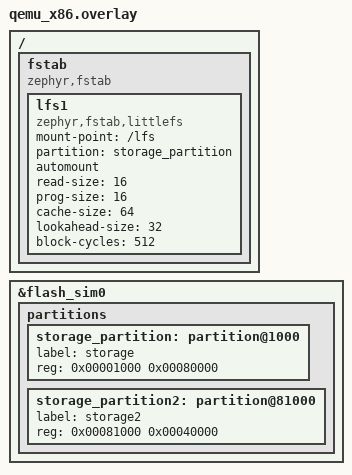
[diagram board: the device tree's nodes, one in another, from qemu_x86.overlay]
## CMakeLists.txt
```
cmake_minimum_required(VERSION 3.20.0)

set(ZEPHYR_EXTRA_MODULES ${CMAKE_CURRENT_SOURCE_DIR}/modules/lua)
set(DTC_OVERLAY_FILE "qemu_x86.overlay")

find_package(Zephyr)
project(zephyr_qemu_lua_demo)

set(embedded_lua_scripts "")
file(GLOB files "${CMAKE_CURRENT_SOURCE_DIR}/src/lua_scripts/*.lua")
foreach(file ${files})
    get_filename_component(filename ${file} NAME)
    get_filename_component(filepath ${file} PATH)
    message(STATUS "embedding ${filepath}/${filename} into elf")
    add_custom_command(
        OUTPUT ${CMAKE_CURRENT_BINARY_DIR}/embluaobj/${filename}.o
        WORKING_DIRECTORY ${filepath}
        COMMAND ${CMAKE_OBJCOPY}
        ARGS -I binary --output-target elf32-i386 --binary-architecture i386 ${filename} ${CMAKE_CURRENT_BINARY_DIR}/embluaobj/${filename}.o
    )
    # Find a way to automatically choose output-target and binary-architecture
    #   e.g. using : $<TARGET_PROPERTY:bintools,elfconvert_flag_outtarget>
    list(APPEND embedded_lua_scripts ${CMAKE_CURRENT_BINARY_DIR}/embluaobj/${filename}.o)
endforeach()

FILE(GLOB app_sources src/*.c*)
target_sources(app PRIVATE ${app_sources} ${embedded_lua_scripts})

zephyr_linker_sources(SECTIONS iterables.ld)
```

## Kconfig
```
mainmenu "Networking ZEPHYR QEMU AWS MQTT sample application"

config CLOUD_AWS_HOSTNAME
	string "AWS MQTT hostname"
	help
		Hostname of the AWS MQTT broker.

config CLOUD_AWS_PORT
	int "AWS MQTT port"
	default 8883
	help
		Port of the AWS MQTT broker.

config CLOUD_AWS_DEVICE_NAME
	string "AWS Device name"
	help
		Name of the device.

config CLOUD_AWS_QOS
	int "AWS MQTT QoS"
	default 0
	help
		Quality of Service of the AWS MQTT broker.

config CLOUD_AWS_PAYLOAD_BUFFER_SIZE
	int "AWS MQTT payload buffer size"
	default 4096
	help
		Size of the payload buffer.

source "Kconfig.zephyr"
```

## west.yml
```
# Copyright (c) 2021 Nordic Semiconductor ASA
# SPDX-License-Identifier: Apache-2.0

manifest:
  self:
    path: zephyr-qemu-dev

  remotes:
    - name: zephyrproject-rtos
      url-base: https://github.com/zephyrproject-rtos

  projects:
    - name: zephyr
      remote: zephyrproject-rtos
      revision: main
      import: true
```

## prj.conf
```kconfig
CONFIG_PRINTK=y

###############################################################################

CONFIG_QEMU_ICOUNT=n

###############################################################################

# CONFIG_NEWLIB_LIBC=y
# CONFIG_NEWLIB_LIBC_MIN_REQUIRED_HEAP_SIZE=2048

CONFIG_MINIMAL_LIBC=y
CONFIG_MINIMAL_LIBC_MALLOC=y
CONFIG_MINIMAL_LIBC_MALLOC_ARENA_SIZE=2048

CONFIG_SYS_MEM_BLOCKS=y
```

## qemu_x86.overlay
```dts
/delete-node/ &storage_partition;

/ {
	fstab {
		compatible = "zephyr,fstab";
		lfs1: lfs1 {
			compatible = "zephyr,fstab,littlefs";
			mount-point = "/lfs";
			partition = <&storage_partition>;
			automount;
			read-size = <16>;
			prog-size = <16>;
			cache-size = <64>;
			lookahead-size = <32>;
			block-cycles = <512>;
		};
	};
};

&flash_sim0 {
	partitions {
		storage_partition: partition@1000 {
			label = "storage";
			reg = <0x00001000 0x00080000>;
		};

		/* Todo, use this partition with FATFS NAND: (DISK_DRIVER_FLASH) 
		 * With big sector size
		 * erase-block-size = < 0x400 >;
		 * write-block-size = < 0x4 >;
		 */
		storage_partition2: partition@81000 {
			label = "storage2";
			reg = <0x00081000 0x00040000>;
		};
    };
};
```

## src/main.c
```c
#include <zephyr.h>

#include <stdio.h>
#include <stdlib.h>
#include <errno.h>
#include <stdio.h>

#include <sys/mem_blocks.h>

SYS_MEM_BLOCKS_DEFINE_STATIC(memblocks, 0x100, 4, 4);

int main(void)
{
	void *blocks[4];
	int ret = sys_mem_blocks_alloc(&memblocks, 2, blocks);
	printk("sys_mem_blocks_alloc : ret: %d\n", ret);

	if (ret == 0) {
		printk("blocks: %p %p\n", blocks[0], blocks[1]);
		sys_mem_blocks_free(&memblocks, 2, blocks);
		printk("sys_mem_blocks_free : ret: %d\n", ret);
	}

	void *alloc;
	ret = sys_mem_blocks_alloc(&memblocks, 1, &alloc);
	printk("sys_mem_blocks_alloc : ret: %d\n", ret);

	if (ret == 0) {
		printk("blocks: %p\n", alloc);
		sys_mem_blocks_free(&memblocks, 1, &alloc);
		printk("sys_mem_blocks_free : ret: %d\n", ret);
	}

	return 0;
}
```

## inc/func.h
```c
#ifndef _FUNC_H_
#define _FUNC_H_

void hello(void);

#endif /* _FUNC_H_ */
```

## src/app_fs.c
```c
/*
 * Copyright (c) 2022 Lucas Dietrich
 * Copyright (c) 2022 Lukasz Majewski, DENX Software Engineering GmbH
 * Copyright (c) 2019 Peter Bigot Consulting, LLC
 *
 * SPDX-License-Identifier: Apache-2.0
 */

/* Sample which uses the filesystem API with littlefs */

#include <stdio.h>

#include <zephyr.h>
#include <device.h>

#include <fs/fs.h>
#include <fs/littlefs.h>
#include <ff.h>

#include <storage/flash_map.h>
#include <storage/disk_access.h>

#include <logging/log.h>
LOG_MODULE_REGISTER(app_fs, LOG_LEVEL_DBG);

static int lsdir(const char *path)
{
	int res;
	struct fs_dir_t dirp;
	static struct fs_dirent entry;

	fs_dir_t_init(&dirp);

	/* Verify fs_opendir() */
	res = fs_opendir(&dirp, path);
	if (res) {
		LOG_ERR("Error opening dir %s [%d]", path, res);
		return res;
	}

	LOG_INF("Listing dir %s ...", path);
	for (;;) {
		/* Verify fs_readdir() */
		res = fs_readdir(&dirp, &entry);

		/* entry.name[0] == 0 means end-of-dir */
		if (res || entry.name[0] == 0) {
			if (res < 0) {
				LOG_ERR("Error reading dir [%d]", res);
			}
			break;
		}

		if (entry.type == FS_DIR_ENTRY_DIR) {
			LOG_INF("[DIR ] %s", entry.name);
		} else {
			LOG_INF("[FILE] %s (size = %zu)",
				   entry.name, entry.size);
		}
	}

	/* Verify fs_closedir() */
	fs_closedir(&dirp);

	return res;
}


static int littlefs_flash_erase(unsigned int id)
{
	const struct flash_area *pfa;
	int rc;

	rc = flash_area_open(id, &pfa);
	if (rc < 0) {
		LOG_ERR("FAIL: unable to find flash area %u: %d",
			id, rc);
		return rc;
	}

	LOG_INF("Area %u at 0x%x on %s for %u bytes",
		   id, (unsigned int)pfa->fa_off, pfa->fa_dev_name,
		   (unsigned int)pfa->fa_size);

	/* Optional wipe flash contents */
	if (IS_ENABLED(CONFIG_APP_WIPE_STORAGE)) {
		rc = flash_area_erase(pfa, 0, pfa->fa_size);
		LOG_ERR("Erasing flash area ... %d", rc);
	}

	flash_area_close(pfa);
	return rc;
}

/* LittleFS mount point */
#define LFS_PARTITION_NODE DT_NODELABEL(lfs1)
#define FATFS_PARTITION_NODE DT_NODELABEL(fatfs1)

#if DT_NODE_EXISTS(LFS_PARTITION_NODE)
FS_FSTAB_DECLARE_ENTRY(LFS_PARTITION_NODE);
#else /* LFS_PARTITION_NODE */
FS_LITTLEFS_DECLARE_DEFAULT_CONFIG(storage);
static struct fs_mount_t lfs_storage_mnt = {
	.type = FS_LITTLEFS,
	.fs_data = &storage,
	.storage_dev = (void *)FLASH_AREA_ID(storage),
	.mnt_point = "/lfs",
};
#endif /* LFS_PARTITION_NODE */

	struct fs_mount_t *mp =
#if DT_NODE_EXISTS(LFS_PARTITION_NODE)
		&FS_FSTAB_ENTRY(LFS_PARTITION_NODE)
#else
		&lfs_storage_mnt
#endif
		;

/* FATFS mount point */
static FATFS fat_fs;

static struct fs_mount_t mp2 = {
	.type = FS_FATFS,
	.fs_data = &fat_fs,
};

static const char *disk_mount_pt = "/RAM:";

int fs_stats(void)
{
	int rc;
	struct fs_statvfs sbuf;

	rc = fs_statvfs(mp->mnt_point, &sbuf);
	if (rc < 0) {
		LOG_INF("FAIL: statvfs: %d", rc);
		goto exit;
	}

	LOG_INF("%s: bsize = %lu ; frsize = %lu ;"
		   " blocks = %lu ; bfree = %lu",
		   mp->mnt_point,
		   sbuf.f_bsize, sbuf.f_frsize,
		   sbuf.f_blocks, sbuf.f_bfree);

	rc = lsdir(mp->mnt_point);
	if (rc < 0) {
		LOG_INF("FAIL: lsdir %s: %d", mp->mnt_point, rc);
		goto exit;
	}

	rc = 0;

exit:
	return rc;
}

static int fatfs_mount(void)
{
	int rc;

	/* raw disk i/o */
	do {
		static const char *disk_pdrv = "RAM";
		uint64_t memory_size_mb;
		uint32_t block_count;
		uint32_t block_size;

		if (disk_access_init(disk_pdrv) != 0) {
			LOG_ERR("Storage init ERROR!");
			break;
		}

		if (disk_access_ioctl(disk_pdrv,
				DISK_IOCTL_GET_SECTOR_COUNT, &block_count)) {
			LOG_ERR("Unable to get sector count");
			break;
		}
		LOG_INF("Block count %u", block_count);

		if (disk_access_ioctl(disk_pdrv,
				DISK_IOCTL_GET_SECTOR_SIZE, &block_size)) {
			LOG_ERR("Unable to get sector size");
			break;
		}
		printk("Sector size %u\n", block_size);

		memory_size_mb = (uint64_t)block_count * block_size;
		printk("Memory Size(MB) %u\n", (uint32_t)(memory_size_mb >> 20));
	} while (0);

	mp2.mnt_point = disk_mount_pt;

	rc = fs_mount(&mp2);

	if (rc == FR_OK) {
		printk("Disk mounted.\n");
		lsdir(disk_mount_pt);
	} else {
		printk("Error mounting disk.\n");
	}

	return rc;
}

static int littlefs_mount(void)
{
	int rc;

	rc = littlefs_flash_erase((uintptr_t)mp->storage_dev);
	if (rc < 0) {
		return rc;
	}

	/* Do not mount if auto-mount has been enabled */
#if !DT_NODE_EXISTS(LFS_PARTITION_NODE) ||						\
	!(FSTAB_ENTRY_DT_MOUNT_FLAGS(LFS_PARTITION_NODE) & FS_MOUNT_FLAG_AUTOMOUNT)
	rc = fs_mount(mp);
	if (rc < 0) {
		LOG_INF("FAIL: mount id %" PRIuPTR " at %s: %d",
		       (uintptr_t)mp->storage_dev, mp->mnt_point, rc);
		return rc;
	}
	LOG_INF("%s mount: %d", mp->mnt_point, rc);
#else
	LOG_INF("%s automounted", mp->mnt_point);
#endif

	return rc;
}

int fs_init(void)
{
	int rc;

	rc = fatfs_mount();
	if (rc < 0) {
		return rc;
	}

	rc = littlefs_mount();

	return rc;
}

int fs_file_add(const char *fname, const char *data, size_t size)
{
	int rc, written = 0;
	struct fs_file_t file;

	fs_file_t_init(&file);
	rc = fs_open(&file, fname, FS_O_CREATE | FS_O_WRITE);
	if (rc < 0) {
		LOG_ERR("FAIL: open %s: %d", log_strdup(fname), rc);
		return rc;
	}

	rc = fs_seek(&file, 0, FS_SEEK_SET);
	if (rc < 0) {
		LOG_ERR("FAIL: seek %s: %d", log_strdup(fname), rc);
		goto out;
	}

	rc = fs_write(&file, data, size);
	if (rc < 0) {
		LOG_ERR("FAIL: write %s: %d", log_strdup(fname), rc);
		goto out;
	}

	written = rc;

out:
	rc = fs_close(&file);
	if (rc < 0) {
		LOG_ERR("FAIL: close %s: %d", log_strdup(fname), rc);
		return rc;
	}

	return written;
}
```

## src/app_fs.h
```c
#ifndef _LUA_FS_H_
#define _LUA_FS_H_

#include <fs/fs.h>

extern struct fs_mount_t *mp;

int fs_init(void);

int fs_file_add(const char *name, const char *data, size_t size);

int fs_stats(void);

#endif /* _LUA_FS_H_ */
```

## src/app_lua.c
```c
#include "app_lua.h"

#include <stdlib.h>
#include <sys/times.h>
#include <string.h>

#include <zephyr.h>
#include <assert.h>

#include <lua/lua.h>
#include <lua/lauxlib.h>
#include <lua/lualib.h>

#include <fs/fs.h>

#include "app_fs.h"

#include <logging/log.h>
LOG_MODULE_REGISTER(app_lua, LOG_LEVEL_DBG);

#define DUMMY_STDLIB_FUNCTIONS
#ifdef DUMMY_STDLIB_FUNCTIONS
/* https://man7.org/linux/man-pages/man2/times.2.html */
clock_t _times(struct tms* tms)
{
	__ASSERT(0, "_times not implemented");
	return (clock_t) -1;
}

/* https://man7.org/linux/man-pages/man2/unlink.2.html */
/* http://manpagesfr.free.fr/man/man2/unlink.2.html */
int _unlink(const char *pathname)
{
	__ASSERT(0, "_unlink not implemented");
	return -1;
}

/* https://man7.org/linux/man-pages/man2/link.2.html */
int _link(const char *oldpath, const char *newpath)
{
	__ASSERT(0, "_link not implemented");
	return -1;
}
#endif

int app_lua_string_test(void)
{
	int res;
	printk("LUA starting ...\n");

	lua_writestring(LUA_COPYRIGHT, strlen(LUA_COPYRIGHT));
	lua_writeline();

	lua_State *L = luaL_newstate();
	luaL_openlibs(L);
	luaL_loadstring(L, "print('Hello from LUA running on Zephyr RTOS !')");
	res = lua_pcall(L, 0, LUA_MULTRET, 0);
	lua_close(L);

	printk("LUA done ... : %d\n", res);

	return 0;
}

int app_lua_execute_script(const char *name)
{
	int res;

	lua_State *L = luaL_newstate();
	luaL_openlibs(L);

	res = luaL_loadfile(L, name);
	lua_pcall(L, 0, LUA_MULTRET, 0);

	lua_close(L);

	return res;
}
```

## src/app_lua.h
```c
#ifndef _LUA_H_
#define _LUA_H_

int app_lua_string_test(void);

int app_lua_execute_script(const char *name);

#endif /* _LUA_H_ */
```

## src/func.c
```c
#include "func.h"

#include <kernel.h>

void hello(void)
{
    printk("[%u] Hello from QEMU !\n", k_uptime_get_32());
}
```

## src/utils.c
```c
#include "utils.h"

uint32_t utils_genrdm(void)
{
	static uint32_t i = 0;

	i = 100000U + (i * 7777U) + (i * i);

	return i;
}
```

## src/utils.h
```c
#ifndef _APP_UTILS_H_
#define _APP_UTILS_H_

#include <stdint.h>

uint32_t utils_genrdm(void);

#endif /* _APP_UTILS_H_ */
```
